# GD32E53x register map
File version: 1.0
CPU: CM33 r0p4, little endian, MPU, FPU, 4 interrupt priority bits
Registers are 32-bit, read-write, reset 0x0 unless marked. A register's access mark holds for its fields unless they carry their own. Offsets are from the block's base; [hi:lo] are bit positions; {n}, {i} and the like mark numbered series.

## TIMER0 — Advanced-timers
Base 0x40012C00
Same registers: TIMER7 0x40013400, TIMER19 0x40014800
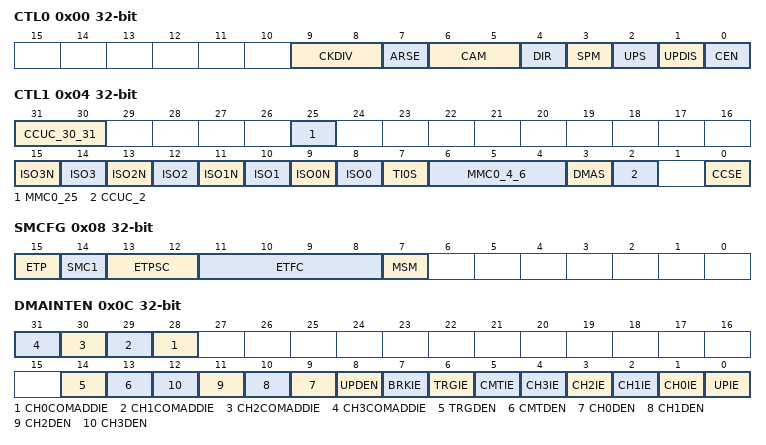
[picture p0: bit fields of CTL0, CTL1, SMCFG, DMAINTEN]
0x00 CTL0 — Control register 0
  [9:8] CKDIV — Clock division
  [7] ARSE — Auto-reload shadow enable
  [6:5] CAM — Counter align mode selection
  [4] DIR — Direction
  [3] SPM — Single pulse mode
  [2] UPS — Update source
  [1] UPDIS — Update disable
  [0] CEN — Counter enable
0x04 CTL1 — Control register 1
  [31:30] CCUC_30_31 — Commutation control shadow register update control
  [25] MMC0_25 — Master mode control 0
  [15] ISO3N — Idle state of multi mode channel 3 complementary output.
  [14] ISO3 — Idle state of channel 3 output.
  [13] ISO2N — Idle state of multi mode channel 2 complementary output.
  [12] ISO2 — Idle state of channel 2 output
  [11] ISO1N — Idle state of multi mode channel 1 complementary output
  [10] ISO1 — Idle state of channel 1 output
  [9] ISO0N — Idle state of multi mode channel 0 complementary output
  [8] ISO0 — Idle state of channel 0 output
  [7] TI0S — Channel 0 trigger input selection
  [6:4] MMC0_4_6 — Master mode control 0
  [3] DMAS — DMA request source selection
  [2] CCUC_2 — Commutation control shadow register update control
  [0] CCSE — Commutation control shadow enable
0x08 SMCFG — Slave mode configuration register
  [15] ETP — External trigger polarity
  [14] SMC1 — Part of slave mode controller is used to enable external clock mode 1
  [13:12] ETPSC — External trigger prescaler
  [11:8] ETFC — External trigger filter control
  [7] MSM — Master-slave mode
0x0C DMAINTEN — DMA and interrupt enable register
  [n+28] CH{n}COMADDIE (n=0..3) — Channel {n} additional compare interrupt enable
  [14] TRGDEN — Trigger DMA request enable
  [13] CMTDEN — Commutation DMA request enable
  [n+9] CH{n}DEN (n=0..3) — Channel {n} capture/compare DMA request enable
  [8] UPDEN — Update DMA request enable
  [7] BRKIE — Break interrupt enable
  [6] TRGIE — Trigger interrupt enable
  [5] CMTIE — Commutation interrupt enable
  [n+1] CH{n}IE (n=0..3) — Channel {n} capture/compare interrupt enable
  [0] UPIE — Update interrupt enable
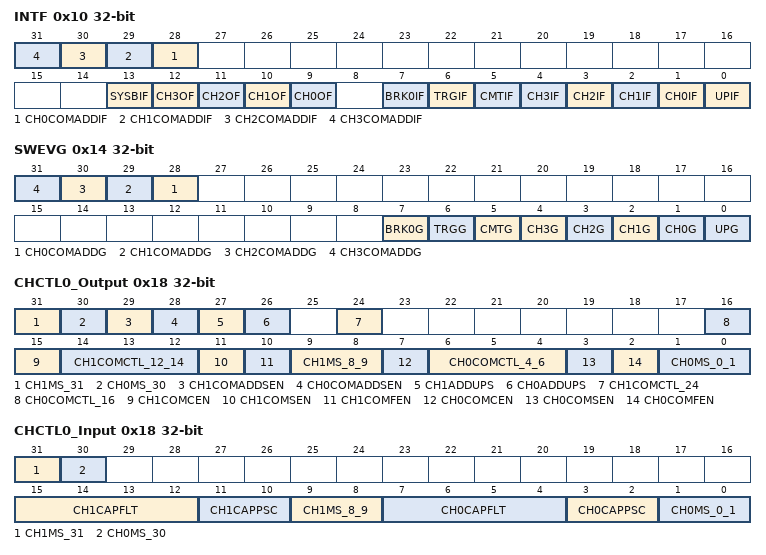
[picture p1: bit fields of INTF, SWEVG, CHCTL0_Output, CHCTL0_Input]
0x10 INTF — Interrupt flag register
  [n+28] CH{n}COMADDIF (n=0..3) — Channel {n} additional compare interrupt flag.
  [13] SYSBIF — System source break interrupt flag
  [n+9] CH{n}OF (n=0..3) — Channel {n} over capture flag
  [7] BRK0IF — BREAK0 interrupt flag
  [6] TRGIF — Trigger interrupt flag
  [5] CMTIF — Channel commutation interrupt flag
  [n+1] CH{n}IF (n=0..3) — Channel {n} capture/compare interrupt flag
  [0] UPIF — Update interrupt flag
0x14 SWEVG wo — Software event generation register
  [n+28] CH{n}COMADDG (n=0..3) — Channel {n} additional compare event generation.
  [7] BRK0G — BREAK0 event generation
  [6] TRGG — Trigger event generation
  [5] CMTG — Channel commutation event generation
  [n+1] CH{n}G (n=0..3) — Channel {n} capture or compare event generation
  [0] UPG — Update event generation
0x18 CHCTL0_Output — Channel control register 0 (output mode)
  [31] CH1MS_31 — Channel 1 I/O mode selection
  [30] CH0MS_30 — Channel 0 I/O mode selection
  [29] CH1COMADDSEN — Channel 1 additional compare output shadow enable
  [28] CH0COMADDSEN — Channel 0 additional compare output shadow enable
  [27] CH1ADDUPS — Channel 1 additional update source
  [26] CH0ADDUPS — Channel 0 additional update source
  [24] CH1COMCTL_24 — Channel 1 compare output control
  [16] CH0COMCTL_16 — Channel 0 compare output control
  [15] CH1COMCEN — Channel 1 output compare clear enable
  [14:12] CH1COMCTL_12_14 — Channel 1 compare output control
  [11] CH1COMSEN — Channel 1 output compare shadow enable
  [10] CH1COMFEN — Channel 1 output compare fast enable
  [9:8] CH1MS_8_9 — Channel 1 mode selection
  [7] CH0COMCEN — Channel 0 output compare clear enable
  [6:4] CH0COMCTL_4_6 — Channel 0 compare output control
  [3] CH0COMSEN — Channel 0 compare output shadow enable
  [2] CH0COMFEN — Channel 0 output compare fast enable
  [1:0] CH0MS_0_1 — Channel 0 I/O mode selection
0x18 CHCTL0_Input (alternate view of CHCTL0_Output) — Channel control register 0 (input mode)
  [31] CH1MS_31 — Channel 1 I/O mode selection
  [30] CH0MS_30 — Channel 0 I/O mode selection
  [15:12] CH1CAPFLT — Channel 1 input capture filter control
  [11:10] CH1CAPPSC — Channel 1 input capture prescaler
  [9:8] CH1MS_8_9 — Channel 1 mode selection
  [7:4] CH0CAPFLT — Channel 0 input capture filter control
  [3:2] CH0CAPPSC — Channel 0 input capture prescaler
  [1:0] CH0MS_0_1 — Channel 0 mode selection
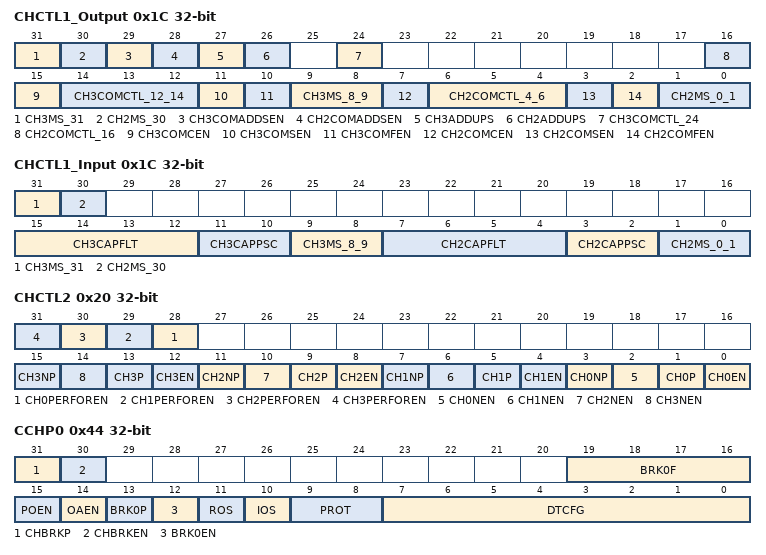
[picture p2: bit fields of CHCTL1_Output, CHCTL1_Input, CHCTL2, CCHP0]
0x1C CHCTL1_Output — Channel control register 1 (output mode)
  [31] CH3MS_31 — Channel 3 I/O mode selection
  [30] CH2MS_30 — Channel 2 I/O mode selection
  [29] CH3COMADDSEN — Channel 3 additional compare output shadow enable
  [28] CH2COMADDSEN — Channel 2 additional compare output shadow enable
  [27] CH3ADDUPS — Channel 3 additional update source
  [26] CH2ADDUPS — Channel 2 additional update source
  [24] CH3COMCTL_24 — Channel 3 compare output control
  [16] CH2COMCTL_16 — Channel 2 compare output control
  [15] CH3COMCEN — Channel 3 output compare clear enable
  [14:12] CH3COMCTL_12_14 — Channel 3 compare output control
  [11] CH3COMSEN — Channel 3 output compare shadow enable
  [10] CH3COMFEN — Channel 3 output compare fast enable
  [9:8] CH3MS_8_9 — Channel 3 mode selection
  [7] CH2COMCEN — Channel 2 output compare clear enable
  [6:4] CH2COMCTL_4_6 — Channel 2 compare output control
  [3] CH2COMSEN — Channel 2 compare output shadow enable
  [2] CH2COMFEN — Channel 2 output compare fast enable
  [1:0] CH2MS_0_1 — Channel 2 I/O mode selection
0x1C CHCTL1_Input (alternate view of CHCTL1_Output) — Channel control register 1 (input mode)
  [31] CH3MS_31 — Channel 3 I/O mode selection
  [30] CH2MS_30 — Channel 2 I/O mode selection
  [15:12] CH3CAPFLT — Channel 3 input capture filter control
  [11:10] CH3CAPPSC — Channel 3 input capture prescaler
  [9:8] CH3MS_8_9 — Channel 3 mode selection
  [7:4] CH2CAPFLT — Channel 2 input capture filter control
  [3:2] CH2CAPPSC — Channel 2 input capture prescaler
  [1:0] CH2MS_0_1 — Channel 2 mode selection
0x20 CHCTL2 — Channel control register 2
  [n+28] CH{n}PERFOREN (n=0..3) — Channel {n} in the composite PWM or asymmetric PWM mode, the period point match moment O{n}CPRE level setting
  [4n+3] CH{n}NP (n=0..3) — Channel {n} complementary output polarity
  [4n+2] CH{n}NEN (n=0..3) — Channel {n} complementary output enable
  [4n+1] CH{n}P (n=0..3) — Channel {n} capture/compare polarity
  [4n] CH{n}EN (n=0..3) — Channel {n} capture/compare enable
0x24 CNT — Counter register
  [15:0] CNT — This bit-field indicates the current counter value. Writing to this bit-field can change the value of the counter.
0x28 PSC — Prescaler register
  [15:0] PSC — Prescaler value of the counter clock
0x2C CAR reset 0xFFFF — Counter auto reload register
  [15:0] CARL — Counter auto reload value
0x30 CREP0 — Counter repetition register 0
  [7:0] CREP0 — Counter repetition value 0
{0x34+4i} CH{i}CV (i=0..3) — Channel {i} capture/compare value register
  [15:0] CH{i}VAL — Capture/compare value of channel {i}
0x44 CCHP0 — Complementary channel protection register 0
  [31] CHBRKP — Channel BREAK input signal polarity
  [30] CHBRKEN — Channel BREAK input signal enable
  [19:16] BRK0F — BREAK0 input signal filter
  [15] POEN — Primary output enable
  [14] OAEN — Output automatic enable
  [13] BRK0P — BREAK0 input signal polarity
  [12] BRK0EN — BREAK0 input signal enable
  [11] ROS — Run mode off-state enable
  [10] IOS — Idle mode off-state enable
  [9:8] PROT — Complementary register protect control
  [7:0] DTCFG — Dead time configuration
{0x64+4i} CH{i}COMV_ADD (i=0..3) — Channel {i} additional compare value register
  [15:0] CH{i}COMVAL_ADD — Additional compare value of channel {i}
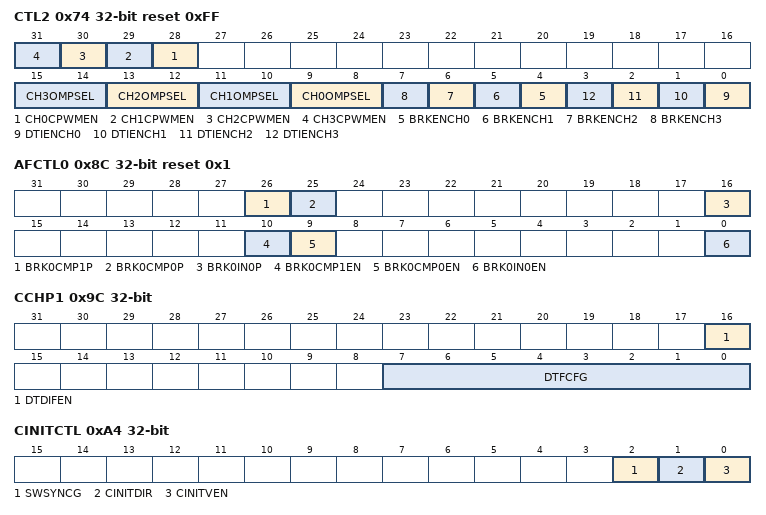
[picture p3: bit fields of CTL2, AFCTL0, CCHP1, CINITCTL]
0x74 CTL2 reset 0xFF — Control register 2
  [n+28] CH{n}CPWMEN (n=0..3) — Channel {n} composite PWM mode enable
  [2n+9:2n+8] CH{n}OMPSEL (n=0..3) — Channel {n} output match pulse select
  [n+4] BRKENCH{n} (n=0..3) — Break control enable for channel {n}
  [n] DTIENCH{n} (n=0..3) — Dead time inserted enable for channel {n}
0x8C AFCTL0 reset 0x1 — Alternate function control register 0
  [26] BRK0CMP1P — BREAK0 CMP1 input polarity
  [25] BRK0CMP0P — BREAK0 CMP0 input polarity
  [16] BRK0IN0P — BREAK0 BRKIN0 alternate function input polarity
  [10] BRK0CMP1EN — BREAK0 CMP1 enable
  [9] BRK0CMP0EN — BREAK0 CMP0 enable
  [0] BRK0IN0EN — BREAK0 BRKIN0 alternate function input enable
0x9C CCHP1 — Complementary channel protection register 1
  [16] DTDIFEN — Dead time configure different enable
  [7:0] DTFCFG — Dead time falling edge configure
0xA4 CINITCTL access per field — Counter initial control register
  [2] SWSYNCG wo — Soft synchronization event generation
  [1] CINITDIR rw — Counter initial count direction
  [0] CINITVEN rw — Counter initial value register enable
0xA8 CINITV — Counter initial value register
  [15:0] CINITVAL — Counter initial value
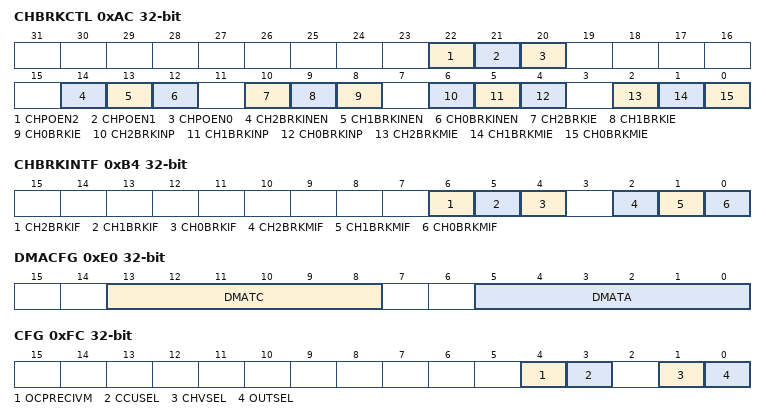
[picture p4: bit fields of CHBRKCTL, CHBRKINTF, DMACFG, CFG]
0xAC CHBRKCTL — Channel break control register
  [22] CHPOEN2 — Channel primary output enable 2
  [21] CHPOEN1 — Channel primary output enable 1
  [20] CHPOEN0 — Channel primary output enable 0
  [14] CH2BRKINEN — Channel 2 BREAK input signal enable
  [13] CH1BRKINEN — Channel 1 BREAK input signal enable
  [12] CH0BRKINEN — Channel 0 BREAK input signal enable
  [10] CH2BRKIE — Channel 2 BREAK interrupt enable
  [9] CH1BRKIE — Channel 1 BREAK interrupt enable
  [8] CH0BRKIE — Channel 0 BREAK interrupt enable
  [6] CH2BRKINP — Channel 2 BREAK input signal polarity
  [5] CH1BRKINP — Channel 1 BREAK input signal polarity
  [4] CH0BRKINP — Channel 0 BREAK input signal polarity
  [2] CH2BRKMIE — Channel 2 BREAK multi-period interrupt enable
  [1] CH1BRKMIE — Channel 1 BREAK multi-period interrupt enable
  [0] CH0BRKMIE — Channel 0 BREAK multi-period interrupt enable
0xB0 CHBRKPER — Channel break period register
  [15:0] PERCNT — Channel BREAK period count
0xB4 CHBRKINTF — Channel break interrupt flag register
  [6] CH2BRKIF — Channel 2 BREAK interrupt flag
  [5] CH1BRKIF — Channel 1 BREAK interrupt flag
  [4] CH0BRKIF — Channel 0 BREAK interrupt flag
  [2] CH2BRKMIF — Channel 2 BREAK multi-period interrupt flag
  [1] CH1BRKMIF — Channel 1 BREAK multi-period interrupt flag
  [0] CH0BRKMIF — Channel 0 BREAK multi-period interrupt flag
0xE0 DMACFG — DMA configuration register
  [13:8] DMATC — DMA transfer count
  [5:0] DMATA — DMA transfer access start address
0xE4 DMATB — DMA transfer buffer register
  [31:0] DMATB — DMA transfer buffer
0xFC CFG — Configuration register
  [4] OCPRECIVM — Output prepare signal clear invalid mode select
  [3] CCUSEL — Commutation control shadow register update select
  [1] CHVSEL — Write CHxVAL register selection bit
  [0] OUTSEL — The output value selection bit
